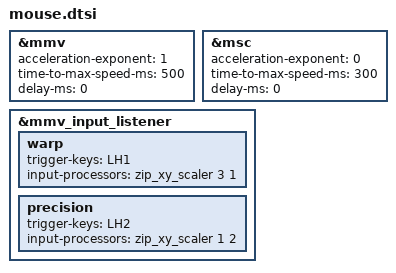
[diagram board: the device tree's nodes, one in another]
#include <dt-bindings/zmk/pointing.h>
#include <input/processors.dtsi>
#include <zephyr/dt-bindings/input/input-event-codes.h>

// Based on @caksoylar's config, defaults in comments
&mmv {
  acceleration-exponent = <1>;          // 1
  time-to-max-speed-ms = <500>;         // 300
  delay-ms = <0>;                       // 0
};

&msc {
  acceleration-exponent = <0>;          // 0
  time-to-max-speed-ms = <300>;         // 300
  delay-ms = <0>;                       // 0
};

&mmv_input_listener {
  warp {
    trigger-keys = <LH1>;
    //layers = <NAV>; 
    input-processors = <&zip_xy_scaler 3 1>;
  };
  precision {
    trigger-keys = <LH2>;
    //layers = <FN>; // Slows down the mouse whenever this layer is active
    input-processors = <&zip_xy_scaler 1 2>;
  };
};

#define U_MS_U &mmv MOVE_UP
#define U_MS_D &mmv MOVE_DOWN
#define U_MS_L &mmv MOVE_LEFT
#define U_MS_R &mmv MOVE_RIGHT
#define U_WH_U &msc SCRL_UP
#define U_WH_D &msc SCRL_DOWN
#define U_WH_L &msc SCRL_LEFT
#define U_WH_R &msc SCRL_RIGHT
